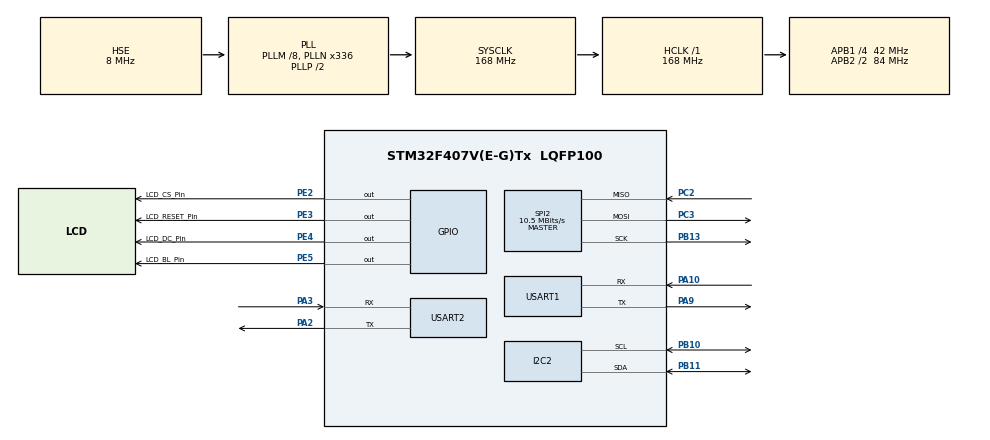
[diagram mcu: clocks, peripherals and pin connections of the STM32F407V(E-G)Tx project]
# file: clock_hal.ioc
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Dma.Request0=SPI2_TX
Dma.SPI2_TX.0.Direction=DMA_MEMORY_TO_PERIPH
Dma.SPI2_TX.0.FIFOMode=DMA_FIFOMODE_DISABLE
Dma.SPI2_TX.0.Instance=DMA1_Stream4
Dma.SPI2_TX.0.MemDataAlignment=DMA_MDATAALIGN_HALFWORD
Dma.SPI2_TX.0.MemInc=DMA_MINC_ENABLE
Dma.SPI2_TX.0.Mode=DMA_NORMAL
Dma.SPI2_TX.0.PeriphDataAlignment=DMA_PDATAALIGN_HALFWORD
Dma.SPI2_TX.0.PeriphInc=DMA_PINC_DISABLE
Dma.SPI2_TX.0.Priority=DMA_PRIORITY_HIGH
FREERTOS.Tasks01=defaultTask,24,128,StartDefaultTask,Default,NULL,Dynamic,NULL,NULL
I2C2.I2C_Mode=I2C_Standard
Mcu.Family=STM32F4
Mcu.Name=STM32F407V(E-G)Tx
Mcu.Package=LQFP100
NVIC.DMA1_Stream4_IRQn=true\:6\:0\:true\:false\:true\:true\:false\:true\:true
NVIC.PriorityGroup=NVIC_PRIORITYGROUP_4
NVIC.TIM1_UP_TIM10_IRQn=true\:15\:0\:false\:false\:true\:false\:false\:true\:true
NVIC.TimeBase=TIM1_UP_TIM10_IRQn
NVIC.TimeBaseIP=TIM1
NVIC.USART1_IRQn=true\:6\:0\:true\:false\:true\:true\:true\:true\:true
NVIC.USART2_IRQn=true\:5\:0\:true\:false\:true\:true\:true\:true\:true
PA10.GPIO_PuPd=GPIO_PULLUP
PA10.GPIO_Speed=GPIO_SPEED_FREQ_HIGH
PA10.Mode=Asynchronous
PA10.Signal=USART1_RX
PA13.Mode=Serial_Wire
PA13.Signal=SYS_JTMS-SWDIO
PA14.Mode=Serial_Wire
PA14.Signal=SYS_JTCK-SWCLK
PA2.GPIO_Speed=GPIO_SPEED_FREQ_HIGH
PA2.Mode=Asynchronous
PA2.Signal=USART2_TX
PA3.GPIO_PuPd=GPIO_PULLUP
PA3.GPIO_Speed=GPIO_SPEED_FREQ_HIGH
PA3.Mode=Asynchronous
PA3.Signal=USART2_RX
PA9.GPIO_Speed=GPIO_SPEED_FREQ_HIGH
PA9.Mode=Asynchronous
PA9.Signal=USART1_TX
PB10.GPIO_Pu=GPIO_PULLUP
PB10.GPIO_Speed=GPIO_SPEED_FREQ_MEDIUM
PB10.Mode=I2C
PB10.Signal=I2C2_SCL
PB11.GPIO_Pu=GPIO_PULLUP
PB11.GPIO_Speed=GPIO_SPEED_FREQ_MEDIUM
PB11.Mode=I2C
PB11.Signal=I2C2_SDA
PB13.Mode=Full_Duplex_Master
PB13.Signal=SPI2_SCK
PC14-OSC32_IN.Mode=LSE-External-Oscillator
PC14-OSC32_IN.Signal=RCC_OSC32_IN
PC15-OSC32_OUT.Mode=LSE-External-Oscillator
PC15-OSC32_OUT.Signal=RCC_OSC32_OUT
PC2.Mode=Full_Duplex_Master
PC2.Signal=SPI2_MISO
PC3.Mode=Full_Duplex_Master
PC3.Signal=SPI2_MOSI
PE2.GPIO_Label=LCD_CS_Pin
PE2.GPIO_Speed=GPIO_SPEED_FREQ_VERY_HIGH
PE2.PinState=GPIO_PIN_SET
PE2.Signal=GPIO_Output
PE3.GPIO_Label=LCD_RESET_Pin
PE3.GPIO_Speed=GPIO_SPEED_FREQ_VERY_HIGH
PE3.PinState=GPIO_PIN_SET
PE3.Signal=GPIO_Output
PE4.GPIO_Label=LCD_DC_Pin
PE4.GPIO_Speed=GPIO_SPEED_FREQ_VERY_HIGH
PE4.PinState=GPIO_PIN_SET
PE4.Signal=GPIO_Output
PE5.GPIO_Label=LCD_BL_Pin
PE5.GPIO_Speed=GPIO_SPEED_FREQ_VERY_HIGH
PE5.PinState=GPIO_PIN_SET
PE5.Signal=GPIO_Output
PH0-OSC_IN.Mode=HSE-External-Oscillator
PH0-OSC_IN.Signal=RCC_OSC_IN
PH1-OSC_OUT.Mode=HSE-External-Oscillator
PH1-OSC_OUT.Signal=RCC_OSC_OUT
ProjectManager.HeapSize=0x200
ProjectManager.StackSize=0x400
ProjectManager.TargetToolchain=CMake
RCC.48MHZClocksFreq_Value=84000000
RCC.AHBFreq_Value=168000000
RCC.APB1CLKDivider=RCC_HCLK_DIV4
RCC.APB1Freq_Value=42000000
RCC.APB1TimFreq_Value=84000000
RCC.APB2CLKDivider=RCC_HCLK_DIV2
RCC.APB2Freq_Value=84000000
RCC.APB2TimFreq_Value=168000000
RCC.CortexFreq_Value=168000000
RCC.HCLKFreq_Value=168000000
RCC.HSE_VALUE=8000000
RCC.HSI_VALUE=16000000
RCC.PLLM=8
RCC.PLLN=336
RCC.PLLSourceVirtual=RCC_PLLSOURCE_HSE
RCC.RCC_RTC_Clock_Source=RCC_RTCCLKSOURCE_LSE
RCC.RCC_RTC_Clock_SourceVirtual=RCC_RTCCLKSOURCE_LSE
RCC.SYSCLKFreq_VALUE=168000000
RCC.SYSCLKSource=RCC_SYSCLKSOURCE_PLLCLK
RCC.VCOOutputFreq_Value=336000000
RTC.Format=RTC_FORMAT_BIN
SPI2.BaudRatePrescaler=SPI_BAUDRATEPRESCALER_4
SPI2.CalculateBaudRate=10.5 MBits/s
SPI2.Direction=SPI_DIRECTION_2LINES
SPI2.Mode=SPI_MODE_MASTER
SPI2.VirtualType=VM_MASTER
USART1.VirtualMode=VM_ASYNC
USART2.VirtualMode=VM_ASYNC
VP_FREERTOS_VS_CMSIS_V2.Mode=CMSIS_V2
VP_RTC_VS_RTC_Activate.Mode=RTC_Enabled
VP_RTC_VS_RTC_Calendar.Mode=RTC_Calendar
VP_SYS_VS_tim1.Mode=TIM1
board=custom

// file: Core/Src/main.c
/* USER CODE BEGIN Header */
/**
  ******************************************************************************
  * @file           : main.c
  * @brief          : Main program body
  ******************************************************************************
  * @attention
  *
  * Copyright (c) 2026 STMicroelectronics.
  * All rights reserved.
  *
  * This software is licensed under terms that can be found in the LICENSE file
  * in the root directory of this software component.
  * If no LICENSE file comes with this software, it is provided AS-IS.
  *
  ******************************************************************************
  */
/* USER CODE END Header */
#include "main.h"
#include "cmsis_os.h"
#include "dma.h"
#include "i2c.h"
#include "rtc.h"
#include "spi.h"
#include "usart.h"
#include "gpio.h"

/* USER CODE BEGIN Includes */
#include "aht20.h"
#include "st7789.h"
/* USER CODE END Includes */

void SystemClock_Config(void);
void MX_FREERTOS_Init(void);

int main(void)
{

  /* MCU Configuration--------------------------------------------------------*/

  /* Reset of all peripherals, Initializes the Flash interface and the Systick. */
  HAL_Init();

  /* Configure the system clock */
  SystemClock_Config();

  /* Initialize all configured peripherals */
  MX_GPIO_Init();
  MX_DMA_Init();
  MX_I2C2_Init();
  MX_SPI2_Init();
  MX_USART1_UART_Init();
  MX_USART2_UART_Init();
  MX_RTC_Init();

  /* Init scheduler */
  osKernelInitialize();  /* Call init function for freertos objects (in cmsis_os2.c) */
  MX_FREERTOS_Init();

  /* Start scheduler */
  osKernelStart();

  /* We should never get here as control is now taken by the scheduler */

  /* Infinite loop */
  while (1)
  {

  }
}

void SystemClock_Config(void)
{
  RCC_OscInitTypeDef RCC_OscInitStruct = {0};
  RCC_ClkInitTypeDef RCC_ClkInitStruct = {0};

  /** Configure the main internal regulator output voltage
  */
  __HAL_RCC_PWR_CLK_ENABLE();
  __HAL_PWR_VOLTAGESCALING_CONFIG(PWR_REGULATOR_VOLTAGE_SCALE1);

  /** Initializes the RCC Oscillators according to the specified parameters
  * in the RCC_OscInitTypeDef structure.
  */
  RCC_OscInitStruct.OscillatorType = RCC_OSCILLATORTYPE_HSE|RCC_OSCILLATORTYPE_LSE;
  RCC_OscInitStruct.HSEState = RCC_HSE_ON;
  RCC_OscInitStruct.LSEState = RCC_LSE_ON;
  RCC_OscInitStruct.PLL.PLLState = RCC_PLL_ON;
  RCC_OscInitStruct.PLL.PLLSource = RCC_PLLSOURCE_HSE;
  RCC_OscInitStruct.PLL.PLLM = 8;
  RCC_OscInitStruct.PLL.PLLN = 336;
  RCC_OscInitStruct.PLL.PLLP = RCC_PLLP_DIV2;
  RCC_OscInitStruct.PLL.PLLQ = 4;
  if (HAL_RCC_OscConfig(&RCC_OscInitStruct) != HAL_OK)
  {
    Error_Handler();
  }

  /** Initializes the CPU, AHB and APB buses clocks
  */
  RCC_ClkInitStruct.ClockType = RCC_CLOCKTYPE_HCLK|RCC_CLOCKTYPE_SYSCLK
                              |RCC_CLOCKTYPE_PCLK1|RCC_CLOCKTYPE_PCLK2;
  RCC_ClkInitStruct.SYSCLKSource = RCC_SYSCLKSOURCE_PLLCLK;
  RCC_ClkInitStruct.AHBCLKDivider = RCC_SYSCLK_DIV1;
  RCC_ClkInitStruct.APB1CLKDivider = RCC_HCLK_DIV4;
  RCC_ClkInitStruct.APB2CLKDivider = RCC_HCLK_DIV2;

  if (HAL_RCC_ClockConfig(&RCC_ClkInitStruct, FLASH_LATENCY_5) != HAL_OK)
  {
    Error_Handler();
  }
}

void HAL_TIM_PeriodElapsedCallback(TIM_HandleTypeDef *htim)
{
  if (htim->Instance == TIM1)
  {
    HAL_IncTick();
  }
}

void Error_Handler(void)
{
  __disable_irq();
  while (1)
  {
  }
}

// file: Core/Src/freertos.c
/* USER CODE BEGIN Header */
/**
  ******************************************************************************
  * File Name          : freertos.c
  * Description        : Code for freertos applications
  ******************************************************************************
  * @attention
  *
  * Copyright (c) 2026 STMicroelectronics.
  * All rights reserved.
  *
  * This software is licensed under terms that can be found in the LICENSE file
  * in the root directory of this software component.
  * If no LICENSE file comes with this software, it is provided AS-IS.
  *
  ******************************************************************************
  */
/* USER CODE END Header */

#include "FreeRTOS.h"
#include "task.h"
#include "main.h"
#include "cmsis_os.h"

/* USER CODE BEGIN Includes */
#include "st7789.h"
#include <stdio.h>
/* USER CODE END Includes */

/* Definitions for defaultTask */
osThreadId_t defaultTaskHandle;
const osThreadAttr_t defaultTask_attributes = {
  .name = "defaultTask",
  .stack_size = 128 * 4,
  .priority = (osPriority_t) osPriorityNormal,
};

void StartDefaultTask(void *argument);

void MX_FREERTOS_Init(void); /* (MISRA C 2004 rule 8.1) */

void MX_FREERTOS_Init(void) {
  /* USER CODE BEGIN Init */
  ST7789_Init();
  /* USER CODE END Init */

  /* Create the thread(s) */
  /* creation of defaultTask */
  defaultTaskHandle = osThreadNew(StartDefaultTask, NULL, &defaultTask_attributes);

}

void StartDefaultTask(void *argument)
{
  /* USER CODE BEGIN StartDefaultTask */
  /* Infinite loop */
  for(;;)
  {
    printf("Hello World!\n");
    osDelay(pdMS_TO_TICKS(1000));
  }
  /* USER CODE END StartDefaultTask */
}
